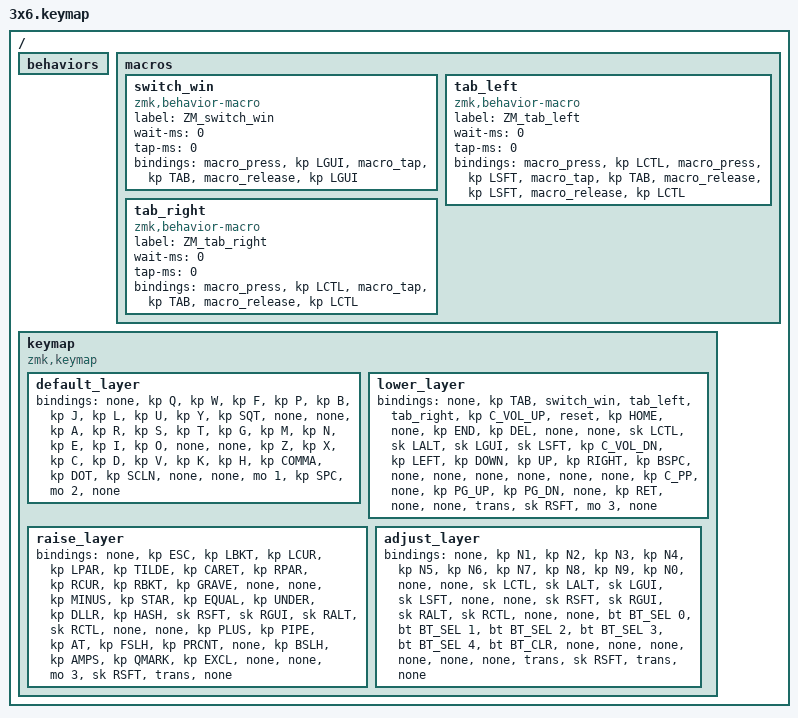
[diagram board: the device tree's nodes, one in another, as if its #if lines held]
#include <behaviors.dtsi>
#include <dt-bindings/zmk/keys.h>
#include <dt-bindings/zmk/bt.h>

/ {
    behaviors {
    };

    macros {
      switch_win: switch_win {
        label = "ZM_switch_win";
        compatible = "zmk,behavior-macro";
        #binding-cells = <0>;
        wait-ms = <0>;
        tap-ms = <0>;
        bindings
           = <&macro_press &kp LGUI>
           , <&macro_tap &kp TAB>
           , <&macro_release &kp LGUI>
           ;
      };
      tab_left: tab_left {
        label = "ZM_tab_left";
        compatible = "zmk,behavior-macro";
        #binding-cells = <0>;
        wait-ms = <0>;
        tap-ms = <0>;
        bindings
           = <&macro_press &kp LCTL>
           , <&macro_press &kp LSFT>
           , <&macro_tap &kp TAB>
           , <&macro_release &kp LSFT>
           , <&macro_release &kp LCTL>
           ;
      };
      tab_right: tab_right {
        label = "ZM_tab_right";
        compatible = "zmk,behavior-macro";
        #binding-cells = <0>;
        wait-ms = <0>;
        tap-ms = <0>;
        bindings
           = <&macro_press &kp LCTL>
           , <&macro_tap &kp TAB>
           , <&macro_release &kp LCTL>
           ;
      };
 
    };

        keymap {
                compatible = "zmk,keymap";

                default_layer {
// ---------------------------------------------------------------------------
// |    |  Q  |  W  |  F  |  P  |  B  |   |  J  |  L  |  U  |  Y  |  '  |    |
// |    |  A  |  R  |  S  |  T  |  G  |   |  M  |  N  |  E  |  I  |  O  |    |
// |    |  Z  |  X  |  C  |  D  |  V  |   |  K  |  H  |  ,  |  .  |  ;  |    |
//                        | LWR | SPC |   | SFT | RSE |
                        bindings = <
   &none &kp Q &kp W &kp F &kp P &kp B     &kp J &kp L &kp U      &kp Y   &kp SQT  &none
   &none &kp A &kp R &kp S &kp T &kp G     &kp M &kp N &kp E      &kp I   &kp O    &none
   &none &kp Z &kp X &kp C &kp D &kp V     &kp K &kp H &kp COMMA  &kp DOT &kp SCLN &none
   #ifdef FIVETHUMBS
                        &none &mo 1 &kp SPC &mo 2 &none
   #else
                   &none &mo 1 &kp SPC     &sk RSFT &mo 2 &none
   #endif
                        >;
                };

                lower_layer {
// -------------------------------------------------------------------------------------
// |    |  tab | swin | tabl | tabr | vlup |   | rset | home | cpsl |  end |  del |    |
// |    | ctrl |  alt |  cmd | shft | vldn |   | left | down |   up | rght | bspc |    |
// |    | spcl | spcr | back |  fwd | play |   |      | pdwn | pgup | swpl | entr |    |
//                           |      |      |   | ADJ  |      |
                        bindings = <
   &none &kp TAB  &switch_win &tab_left &tab_right &kp C_VOL_UP     &reset   &kp HOME  &none     &kp END   &kp DEL  &none
   &none &sk LCTL &sk LALT    &sk LGUI  &sk LSFT   &kp C_VOL_DN     &kp LEFT &kp DOWN  &kp UP    &kp RIGHT &kp BSPC &none
   &none &none    &none       &none     &none      &kp C_PP         &none    &kp PG_UP &kp PG_DN &none     &kp RET  &none
   #ifdef FIVETHUMBS
                                                &none &trans &sk RSFT &mo 3 &none
   #else
                                            &none &trans &trans     &trans &mo 3 &none
   #endif
                       >;
                };

                raise_layer {
// ---------------------------------------------------------------------------
// |    | ESC |  [  |  {  |  (  |  ~  |   |  ^   |  )  |  }  |  ]  |  `  |    |
// |    |  -  |  *  |  =  |  _  |  $  |   |  #  | SFT | CMD | ALT | CTL |    |
// |    |  +  |  |  |  @  |  /  |  %  |   |     |  \  |  &  |  ?  |  !  |    |
//                        |     | ADJ |   |     |     |
                        bindings = <
   &none &kp ESC   &kp LBKT &kp LCUR  &kp LPAR  &kp TILDE     &kp CARET &kp RPAR &kp RCUR &kp RBKT  &kp GRAVE &none
   &none &kp MINUS &kp STAR &kp EQUAL &kp UNDER &kp DLLR      &kp HASH  &sk RSFT &sk RGUI &sk RALT  &sk RCTL  &none
   &none &kp PLUS  &kp PIPE &kp AT    &kp FSLH  &kp PRCNT     &none     &kp BSLH &kp AMPS &kp QMARK &kp EXCL  &none
   #ifdef FIVETHUMBS
                                           &none &mo 3 &sk RSFT &trans &none
   #else
                                       &none &mo 3 &trans     &trans &trans &none
   #endif
                        >;
                };

                adjust_layer {
// -----------------------------------------------------------------------------
// |    |  1  |  2  |  3  |  4  |  5  |   |   6   |  7  |  8  |  9  |  0  |    |  
// |    | CTL | ALT | GUI | SFT |     |   |       | SFT | GUI | ALT | CTL |    |
// |    | bt0 | bt1 | bt2 | bt3 | bt4 |   | btclr |     |     |     |     |    |
//                        |     |     |   |       |     |
                        bindings = <
   &none &kp N1       &kp N2       &kp N3       &kp N4       &kp N5           &kp N6     &kp N7   &kp N8   &kp N9   &kp N0   &none
   &none &sk LCTL     &sk LALT     &sk LGUI     &sk LSFT     &none            &none      &sk RSFT &sk RGUI &sk RALT &sk RCTL &none
   &none &bt BT_SEL 0 &bt BT_SEL 1 &bt BT_SEL 2 &bt BT_SEL 3 &bt BT_SEL 4     &bt BT_CLR &none    &none    &none    &none    &none
   #ifdef FIVETHUMBS
                                                          &none &trans &sk RSFT &trans &none
   #else
                                                      &none &trans &trans     &trans &trans &none
   #endif
                       >;
                };
        };
};
